# S32R372 register map
Vendor: Freescale Semiconductor, Inc.; Series: Qorivva; File version: 1.6
Registers are 32-bit, read-write, reset 0x0 unless marked. A register's access mark holds for its fields unless they carry their own. Offsets are from the block's base; [hi:lo] are bit positions; {n}, {i} and the like mark numbered series; 'fields as' and 'values as' point back to an identical list.

## XBIC_0 — XBIC
Base 0xFC018000; register names take the prefix XBIC_0_
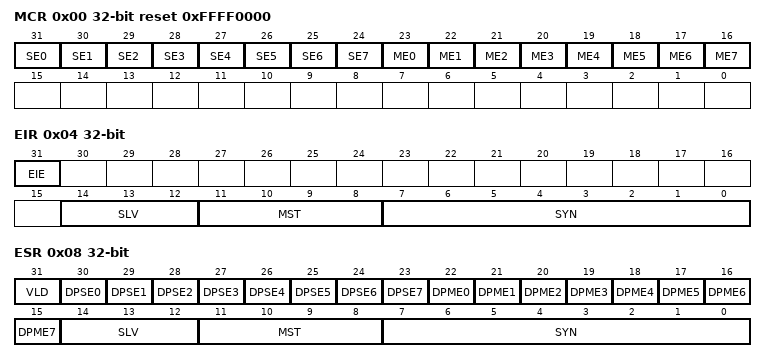
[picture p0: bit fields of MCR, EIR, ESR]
0x00 MCR reset 0xFFFF0000 — XBIC Module Control Register
  [31-n] SE{n} (n=0..7) — Slave Port Enable for EDC error detect.
    0=Attribute integrity checking disabled for slave port {n}; 1=Attribute integrity checking enabled for slave port {n}
  [23-n] ME{n} (n=0..7) — Master Port Enable for slave driven signal safety check.
    0=Attribute integrity checking disabled for master port {n}; 1=Attribute integrity checking enabled for master port {n}
0x04 EIR — XBIC Error Injection Register
  [31] EIE — Error Injection Enable.
    0=Error injection disabled; 1=Error injection enabled
  [14:12] SLV — Target Slave Port
  [11:8] MST — Target Master ID
  [7:0] SYN — Syndrome
0x08 ESR ro — XBIC Error Status Register
  [31] VLD — Error Status Valid.
    0=No error detected, other fields of the ESR and EAR are not valid; 1=Error detected, all fields of the ESR and EAR are valid
  [30-n] DPSE{n} (n=0..7) — Data phase slave port error.
    0=No error on slave port {n}; 1=Data phase error on slave port {n}
  [22-n] DPME{n} (n=0..7) — Data phase master port error.
    0=No error on master port {n}; 1=Data phase error on master port {n}
  [14:12] SLV — Slave Port. The slave port targeted by the last transfer with an error.
  [11:8] MST — Master ID. The master ID value of the last transfer with an error.
  [7:0] SYN — Syndrome
0x0C EAR ro — XBIC Error Address Register
  [31:0] ADDR — The address of the last transfer with an error.

## XBIC_1 — XBIC
Base 0xFC01C000; register names take the prefix XBIC_1_
Registers as XBIC_0.

## XBIC_2 — XBIC
Base 0xFC024000; register names take the prefix XBIC_2_
Registers as XBIC_0.

## XBIC_4 — XBIC
Base 0xFC044000; register names take the prefix XBIC_4_
Registers as XBIC_0.

## PRAMC — RAM controller
Base 0xFC020000; register names take the prefix PRAMC_
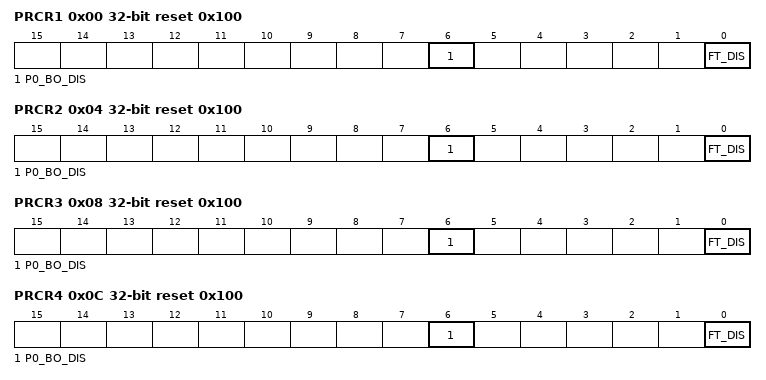
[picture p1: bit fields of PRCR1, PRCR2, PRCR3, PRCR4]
0x00 PRCR1 reset 0x100 — Platform RAM Configuration Register 1
  [6] P0_BO_DIS — Port p0 read burst optimization disable.
    0=64-bit WRP4 read bursts are optimized such that the controller returns a 2-1-1-1 response when PRCR1[FT_DIS]=1; 1=64-bit WRP4 read bursts are not optimized; the controller returns a 2-2-2-2 response when PRCR1[FT_DIS]=1
  [0] FT_DIS — Flow through disabled.
    0=RAM read data is passed directly to the system bus, incurring no additional latency; 1=RAM read data is registered prior to returning on the system bus, incurring 1 extra cycle of latency
0x04 PRCR2 reset 0x100 — Platform RAM Configuration Register 2
  [6] P0_BO_DIS — Port p0 read burst optimization disable.
    0=64-bit WRP4 read bursts are optimized such that the controller returns a 2-1-1-1 response when PRCR2[FT_DIS]=1; 1=64-bit WRP4 read bursts are not optimized; the controller returns a 2-2-2-2 response when PRCR2[FT_DIS]=1
  [0] FT_DIS — Flow through disabled.
    values as PRCR1.FT_DIS
0x08 PRCR3 reset 0x100 — Platform RAM Configuration Register 3
  [6] P0_BO_DIS — Port p0 read burst optimization disable.
    0=64-bit WRP4 read bursts are optimized such that the controller returns a 2-1-1-1 response when PRCR3[FT_DIS]=1; 1=64-bit WRP4 read bursts are not optimized; the controller returns a 2-2-2-2 response when PRCR3[FT_DIS]=1
  [0] FT_DIS — Flow through disabled.
    values as PRCR1.FT_DIS
0x0C PRCR4 reset 0x100 — Platform RAM Configuration Register 4
  [6] P0_BO_DIS — Port p0 read burst optimization disable.
    0=64-bit WRP4 read bursts are optimized such that the controller returns a 2-1-1-1 response when PRCR4[FT_DIS]=1; 1=64-bit WRP4 read bursts are not optimized; the controller returns a 2-2-2-2 response when PRCR4[FT_DIS]=1
  [0] FT_DIS — Flow through disabled.
    values as PRCR1.FT_DIS
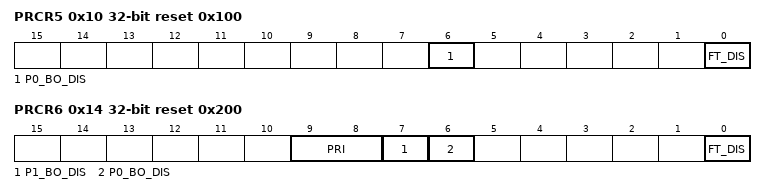
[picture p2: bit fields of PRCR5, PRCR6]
0x10 PRCR5 reset 0x100 — Platform RAM Configuration Register 5
  [6] P0_BO_DIS — Port p0 read burst optimization disable.
    0=64-bit WRP4 read bursts are optimized such that the controller returns a 2-1-1-1 response when PRCR5[FT_DIS]=1; 1=64-bit WRP4 read bursts are not optimized; the controller returns a 2-2-2-2 response when PRCR5[FT_DIS]=1
  [0] FT_DIS — Flow through disabled.
    values as PRCR1.FT_DIS
0x14 PRCR6 reset 0x200 — Platform RAM Configuration Register 6
  [9:8] PRI — AHB port arbitration mode.
    0=Round Robin arbitration is selected; 1=Port p0 has priority over port p1; 2=Port p1 has priority over port p0
  [7] P1_BO_DIS — Port p1 read burst optimization disable.
    0=64-bit WRP4 read bursts are optimized such that the controller returns a 2-1-1-1 response when PRCR8[FT_DIS]=1; 1=64-bit WRP4 read bursts are not optimized; the controller returns a 2-2-2-2 response when PRCR8[FT_DIS]=1
  [6] P0_BO_DIS — Port p0 read burst optimization disable
    values as P1_BO_DIS
  [0] FT_DIS — Flow through disabled.
    values as PRCR1.FT_DIS
